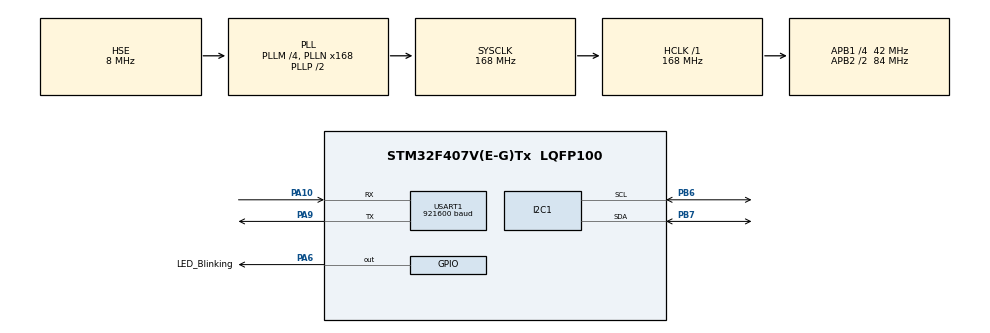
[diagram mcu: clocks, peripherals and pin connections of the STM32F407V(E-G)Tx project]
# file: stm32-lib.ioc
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Mcu.Family=STM32F4
Mcu.Name=STM32F407V(E-G)Tx
Mcu.Package=LQFP100
NVIC.PriorityGroup=NVIC_PRIORITYGROUP_4
NVIC.TIM7_IRQn=true\:0\:0\:false\:false\:true\:true\:true\:true
PA10.Mode=Asynchronous
PA10.Signal=USART1_RX
PA13.Mode=Serial_Wire
PA13.Signal=SYS_JTMS-SWDIO
PA14.Mode=Serial_Wire
PA14.Signal=SYS_JTCK-SWCLK
PA6.GPIO_Label=LED_Blinking
PA6.Signal=GPIO_Output
PA9.Mode=Asynchronous
PA9.Signal=USART1_TX
PB6.Mode=I2C
PB6.Signal=I2C1_SCL
PB7.Mode=I2C
PB7.Signal=I2C1_SDA
PH0-OSC_IN.Mode=HSE-External-Oscillator
PH0-OSC_IN.Signal=RCC_OSC_IN
PH1-OSC_OUT.Mode=HSE-External-Oscillator
PH1-OSC_OUT.Signal=RCC_OSC_OUT
ProjectManager.HeapSize=0x200
ProjectManager.StackSize=0x400
ProjectManager.TargetToolchain=STM32CubeIDE
RCC.48MHZClocksFreq_Value=112000000
RCC.AHBFreq_Value=168000000
RCC.APB1CLKDivider=RCC_HCLK_DIV4
RCC.APB1Freq_Value=42000000
RCC.APB1TimFreq_Value=84000000
RCC.APB2CLKDivider=RCC_HCLK_DIV2
RCC.APB2Freq_Value=84000000
RCC.APB2TimFreq_Value=168000000
RCC.CortexFreq_Value=168000000
RCC.HCLKFreq_Value=168000000
RCC.HSE_VALUE=8000000
RCC.HSI_VALUE=16000000
RCC.LSE_VALUE=32768
RCC.PLLM=4
RCC.PLLN=168
RCC.PLLQ=3
RCC.PLLSourceVirtual=RCC_PLLSOURCE_HSE
RCC.SYSCLKFreq_VALUE=168000000
RCC.SYSCLKSource=RCC_SYSCLKSOURCE_PLLCLK
RCC.VCOOutputFreq_Value=336000000
TIM7.AutoReloadPreload=TIM_AUTORELOAD_PRELOAD_ENABLE
TIM7.Period=5000-1
TIM7.Prescaler=8400-1
USART1.BaudRate=921600
USART1.VirtualMode=VM_ASYNC
VP_TIM7_VS_ClockSourceINT.Mode=Enable_Timer
board=custom

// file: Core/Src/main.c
/* USER CODE BEGIN Header */
/**
  ******************************************************************************
  * @file           : main.c
  * @brief          : Main program body
  ******************************************************************************
  * @attention
  *
  * Copyright (c) 2022 STMicroelectronics.
  * All rights reserved.
  *
  * This software is licensed under terms that can be found in the LICENSE file
  * in the root directory of this software component.
  * If no LICENSE file comes with this software, it is provided AS-IS.
  *
  ******************************************************************************
  */
/* USER CODE END Header */
#include "main.h"

/* USER CODE BEGIN Includes */
#include "log.h"
#include "bh1750.h"
/* USER CODE END Includes */

I2C_HandleTypeDef hi2c1;

TIM_HandleTypeDef htim7;

UART_HandleTypeDef huart1;

void SystemClock_Config(void);
static void MX_GPIO_Init(void);
static void MX_I2C1_Init(void);
static void MX_TIM7_Init(void);
static void MX_USART1_UART_Init(void);
/* USER CODE BEGIN PFP */

void StartBlinkingLedTask(void);

/* USER CODE END PFP */

int main(void)
{

  /* MCU Configuration--------------------------------------------------------*/

  /* Reset of all peripherals, Initializes the Flash interface and the Systick. */
  HAL_Init();

  /* Configure the system clock */
  SystemClock_Config();

  /* USER CODE BEGIN SysInit */

  HAL_Delay(100);

  /* USER CODE END SysInit */

  /* Initialize all configured peripherals */
  MX_GPIO_Init();
  MX_I2C1_Init();
  MX_TIM7_Init();
  MX_USART1_UART_Init();
  /* USER CODE BEGIN 2 */

  StartBlinkingLedTask();

  BH1750_Test();
  /* USER CODE END 2 */

  /* Infinite loop */
  while (1)
  {

  }
}

void SystemClock_Config(void)
{
  RCC_OscInitTypeDef RCC_OscInitStruct = {0};
  RCC_ClkInitTypeDef RCC_ClkInitStruct = {0};

  /** Configure the main internal regulator output voltage
  */
  __HAL_RCC_PWR_CLK_ENABLE();
  __HAL_PWR_VOLTAGESCALING_CONFIG(PWR_REGULATOR_VOLTAGE_SCALE1);

  /** Initializes the RCC Oscillators according to the specified parameters
  * in the RCC_OscInitTypeDef structure.
  */
  RCC_OscInitStruct.OscillatorType = RCC_OSCILLATORTYPE_HSE;
  RCC_OscInitStruct.HSEState = RCC_HSE_ON;
  RCC_OscInitStruct.PLL.PLLState = RCC_PLL_ON;
  RCC_OscInitStruct.PLL.PLLSource = RCC_PLLSOURCE_HSE;
  RCC_OscInitStruct.PLL.PLLM = 4;
  RCC_OscInitStruct.PLL.PLLN = 168;
  RCC_OscInitStruct.PLL.PLLP = RCC_PLLP_DIV2;
  RCC_OscInitStruct.PLL.PLLQ = 3;
  if (HAL_RCC_OscConfig(&RCC_OscInitStruct) != HAL_OK)
  {
    Error_Handler();
  }

  /** Initializes the CPU, AHB and APB buses clocks
  */
  RCC_ClkInitStruct.ClockType = RCC_CLOCKTYPE_HCLK|RCC_CLOCKTYPE_SYSCLK
                              |RCC_CLOCKTYPE_PCLK1|RCC_CLOCKTYPE_PCLK2;
  RCC_ClkInitStruct.SYSCLKSource = RCC_SYSCLKSOURCE_PLLCLK;
  RCC_ClkInitStruct.AHBCLKDivider = RCC_SYSCLK_DIV1;
  RCC_ClkInitStruct.APB1CLKDivider = RCC_HCLK_DIV4;
  RCC_ClkInitStruct.APB2CLKDivider = RCC_HCLK_DIV2;

  if (HAL_RCC_ClockConfig(&RCC_ClkInitStruct, FLASH_LATENCY_5) != HAL_OK)
  {
    Error_Handler();
  }
}

static void MX_I2C1_Init(void)
{

  hi2c1.Instance = I2C1;
  hi2c1.Init.ClockSpeed = 100000;
  hi2c1.Init.DutyCycle = I2C_DUTYCYCLE_2;
  hi2c1.Init.OwnAddress1 = 0;
  hi2c1.Init.AddressingMode = I2C_ADDRESSINGMODE_7BIT;
  hi2c1.Init.DualAddressMode = I2C_DUALADDRESS_DISABLE;
  hi2c1.Init.OwnAddress2 = 0;
  hi2c1.Init.GeneralCallMode = I2C_GENERALCALL_DISABLE;
  hi2c1.Init.NoStretchMode = I2C_NOSTRETCH_DISABLE;
  if (HAL_I2C_Init(&hi2c1) != HAL_OK)
  {
    Error_Handler();
  }

}

static void MX_TIM7_Init(void)
{

  TIM_MasterConfigTypeDef sMasterConfig = {0};

  htim7.Instance = TIM7;
  htim7.Init.Prescaler = 8400-1;
  htim7.Init.CounterMode = TIM_COUNTERMODE_UP;
  htim7.Init.Period = 5000-1;
  htim7.Init.AutoReloadPreload = TIM_AUTORELOAD_PRELOAD_ENABLE;
  if (HAL_TIM_Base_Init(&htim7) != HAL_OK)
  {
    Error_Handler();
  }
  sMasterConfig.MasterOutputTrigger = TIM_TRGO_RESET;
  sMasterConfig.MasterSlaveMode = TIM_MASTERSLAVEMODE_DISABLE;
  if (HAL_TIMEx_MasterConfigSynchronization(&htim7, &sMasterConfig) != HAL_OK)
  {
    Error_Handler();
  }

}

static void MX_USART1_UART_Init(void)
{

  huart1.Instance = USART1;
  huart1.Init.BaudRate = 921600;
  huart1.Init.WordLength = UART_WORDLENGTH_8B;
  huart1.Init.StopBits = UART_STOPBITS_1;
  huart1.Init.Parity = UART_PARITY_NONE;
  huart1.Init.Mode = UART_MODE_TX_RX;
  huart1.Init.HwFlowCtl = UART_HWCONTROL_NONE;
  huart1.Init.OverSampling = UART_OVERSAMPLING_16;
  if (HAL_UART_Init(&huart1) != HAL_OK)
  {
    Error_Handler();
  }

}

static void MX_GPIO_Init(void)
{
  GPIO_InitTypeDef GPIO_InitStruct = {0};

  /* GPIO Ports Clock Enable */
  __HAL_RCC_GPIOH_CLK_ENABLE();
  __HAL_RCC_GPIOA_CLK_ENABLE();
  __HAL_RCC_GPIOB_CLK_ENABLE();

  /*Configure GPIO pin Output Level */
  HAL_GPIO_WritePin(LED_Blinking_GPIO_Port, LED_Blinking_Pin, GPIO_PIN_RESET);

  /*Configure GPIO pin : LED_Blinking_Pin */
  GPIO_InitStruct.Pin = LED_Blinking_Pin;
  GPIO_InitStruct.Mode = GPIO_MODE_OUTPUT_PP;
  GPIO_InitStruct.Pull = GPIO_NOPULL;
  GPIO_InitStruct.Speed = GPIO_SPEED_FREQ_LOW;
  HAL_GPIO_Init(LED_Blinking_GPIO_Port, &GPIO_InitStruct);

}

/* USER CODE BEGIN 4 */

/*
 *	void StartBlinkingLedTask()
 *
 *	Obecnie TIM7 wywoluje przerwania z czestotliwoscia 2Hz i wykonuje toogle'a
 *	na LED_BLINKING.
 */
void StartBlinkingLedTask(void) {

	Log_Info("main", "Starting Blinking Led Task");
	HAL_TIM_Base_Start_IT(&htim7);
}

/* USER CODE END 4 */

void Error_Handler(void)
{
  __disable_irq();
  while (1)
  {
  }
}
